# STM32H723 register map
File version: 2.2
CPU: CM7 r0p1, little endian, MPU, FPU, 4 interrupt priority bits
Registers are 32-bit, read-write, reset 0x0 unless marked. A register's access mark holds for its fields unless they carry their own. Offsets are from the block's base; [hi:lo] are bit positions; {n}, {i} and the like mark numbered series; 'fields as' and 'values as' point back to an identical list.

## DBGMCU — DBGMCU address block description
Base 0x5C001000
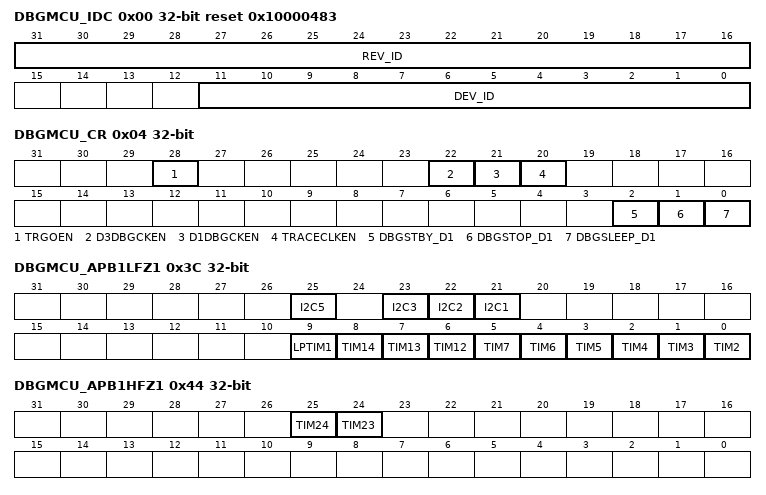
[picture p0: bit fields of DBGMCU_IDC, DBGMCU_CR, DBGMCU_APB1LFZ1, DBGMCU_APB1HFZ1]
0x00 DBGMCU_IDC ro reset 0x10000483
  [31:16] REV_ID — Revision
  [11:0] DEV_ID — Device ID
    0x483=STM32H72x, STM32H73x
0x04 DBGMCU_CR
  [28] TRGOEN — External trigger output enable
    0=Input - TRGIO is connected to TRGIN; 1=Output - TRGIO is connected to TRGOUT
  [22] D3DBGCKEN — D3 debug clock enable
    0=Disabled - D3 domain debug components are disabled and their clocks gated; 1=Enabled - D3 domain debug components are clocked whenever the corresponding domain clock (CK_HCLK_D3) is active
  [21] D1DBGCKEN — D1 debug clock enable
    0=Disabled - D1 domain debug components are disabled and their clocks gated; 1=Enabled - D1 domain debug components are clocked whenever the corresponding domain clock (CK_HCLK_D1) is active
  [20] TRACECLKEN — Trace port clock enable
    0=Disabled - TRACECLK is disabled; 1=Enabled - TRACECLK is active
  [2] DBGSTBY_D1 — D1 domain debug in Standby mode enable
    0=Normal operation - all clocks is disabled and the domain powered down automatically in Standby mode; 1=Automatic clock stop/power-down disabled - all active clocks and oscillators continue to run during Standby mode, and the domain supply is maintained, allowing full debug capability
  [1] DBGSTOP_D1 — D1 domain debug in Stop mode enable
    0=Normal operation - all clocks are disabled automatically in Stop mode; 1=Automatic clock stop disabled - all active clocks and oscillators continue to run during Stop mode, allowing full debug capability
  [0] DBGSLEEP_D1 — D1 domain debug in Sleep mode enable
    0=Normal operation - the processor clock is stopped automatically in Sleep mode; 1=Automatic clock stop disabled - processor clock continues to run, allowing full debug capability
0x34 DBGMCU_APB3FZ1
  [6] WWDG1 — WWDG1 stop in debug
    0=Normal operation - WWDG1 continues to operate while the core is in Debug mode; 1=Stop in debug - WWDG1 is frozen while the core is in Debug mode
0x3C DBGMCU_APB1LFZ1
  [25] I2C5 — I2C5 SMBUS timeout stop in debug
    0=Normal operation - I2C5 SMBUS timeout continues to operate while the core is in Debug mode; 1=Stop in debug - I2C5 SMBUS timeout is frozen while the Cortex-M7 is in Debug mode
  [23] I2C3 — I2C3 SMBUS timeout stop in debug
    0=Normal operation - I2C3 SMBUS timeout continues operating while the core is in Debug mode; 1=Stop in debug - I2C3 SMBUS timeout is frozen while Cortex-M7 is in Debug mode
  [22] I2C2 — I2C2 SMBUS timeout stop in debug
    0=Normal operation - I2C2 SMBUS timeout continues operating while the core is in Debug mode; 1=Stop in debug - I2C2 SMBUS timeout is frozen while Cortex-M7 is in Debug mode
  [21] I2C1 — I2C1 SMBUS timeout stop in debug
    0=Normal operation - I2C1 SMBUS timeout continues operating while the core is in Debug mode; 1=Stop in debug - I2C1 SMBUS timeout is frozen while the core is in Debug mode
  [9] LPTIM1 — LPTIM1 stop in debug
    0=Normal operation - LPTIM1 continues operating while the core is in Debug mode; 1=Stop in debug - LPTIM1 is frozen while Cortex-M7 is in Debug mode
  [8] TIM14 — TIM14 stop in debug
    0=Normal operation - TIM14 continues operating while the core is in Debug mode; 1=Stop in debug - TIM14 is frozen while Cortex-M7 is in Debug mode
  [7] TIM13 — TIM13 stop in debug
    0=Normal operation - TIM13 continues operating while the core is in Debug mode; 1=Stop in debug - TIM13 is frozen while Cortex-M7 is in Debug mode
  [6] TIM12 — TIM12 stop in debug
    0=Normal operation - TIM12 continues operatinge while the core is in Debug mode; 1=Stop in debug - TIM12 is frozen while Cortex-M7 is in Debug mode
  [5] TIM7 — TIM7 stop in debug
    0=Normal operation - TIM7 continues operatinge while the core is in Debug mode; 1=Stop in debug - TIM7 is frozen while Cortex-M7 is in Debug mode
  [n-2] TIM{n} (n=2..6) — TIM{n} stop in debug
    0=Normal operation - TIM{n} continues operating while the core is in Debug mode; 1=Stop in debug - TIM{n} is frozen while Cortex-M7 is in Debug mode
0x44 DBGMCU_APB1HFZ1
  [25] TIM24 — TIM24 stop in debug
    0=Normal operation - TIM24 continues to operate while the core is in debug mode; 1=Stop in debug - TIM24 is frozen while Cortex-M7 is in debug mode
  [24] TIM23 — TIM23 stop in debug
    0=Normal operation - TIM23 continues to operate while the core is in debug mode; 1=Stop in debug - TIM23 is frozen while Cortex-M7 is in debug mode
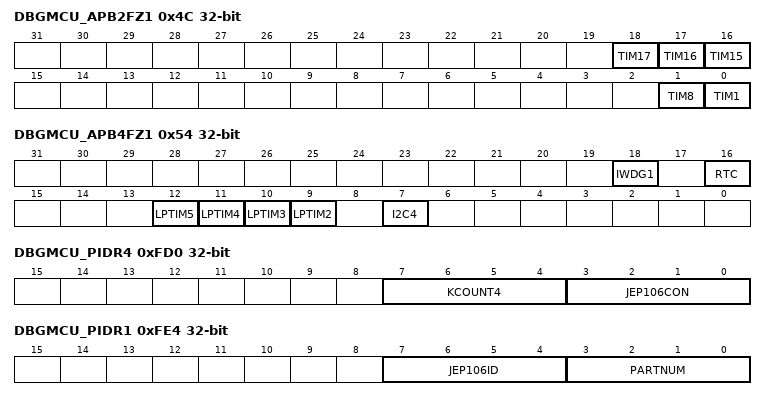
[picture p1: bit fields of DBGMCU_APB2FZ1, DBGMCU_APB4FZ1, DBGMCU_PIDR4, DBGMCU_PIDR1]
0x4C DBGMCU_APB2FZ1
  [18] TIM17 — TIM17 stop in debug
    0=Normal operation - TIM17 continues operating while the core is in Debug mode; 1=Stop in debug - TIM17 is frozen and TIM17 outputs are disabled while Cortex-M7 is in Debug mode
  [17] TIM16 — TIM16 stop in debug
    0=Normal operation - TIM16 continues operating while the core is in Debug mode; 1=Stop in debug - TIM16 is frozen and TIM16 outputs are disabled while Cortex-M7 is in Debug mode
  [16] TIM15 — TIM15 stop in debug
    0=Normal operation - TIM15 continues operating while the core is in Debug mode; 1=Stop in debug - TIM15 is frozen and TIM15 outputs are disabled while Cortex-M7 is in Debug mode
  [1] TIM8 — TIM8 stop in debug
    0=Normal operation - TIM8 continues operating while the core is in Debug mode; 1=Stop in debug - TIM8 is frozen and TIM8 outputs are disabled while Cortex-M7 is in Debug mode
  [0] TIM1 — TIM1 stop in debug
    0=Normal operation - TIM1 continues operating while the core is in Debug mode; 1=Stop in debug - TIM1 is frozen and TIM1 outputs are disabled while Cortex-M7 is in Debug mode
0x54 DBGMCU_APB4FZ1
  [18] IWDG1 — Independent watchdog for D1 stop in debug
    0=Normal operation - watchdog continues counting while the core is in Debug mode; 1=Stop in debug - watchdog is frozen while Cortex-M7 is in Debug mode
  [16] RTC — RTC stop in debug
    0=Normal operation - RTC continues operating while the core is in Debug mode; 1=Stop in debug - RTC is frozen while Cortex-M7 is in Debug mode
  [12] LPTIM5 — LPTIM5 stop in debug
    0=Normal operation - LPTIM5 continues operating while the core is in Debug mode; 1=Stop in debug - LPTIM5 is frozen while Cortex-M7 is in Debug mode
  [11] LPTIM4 — LPTIM4 stop in debug
    0=Normal operation - LPTIM4 continues operating while the core is in Debug mode; 1=Stop in debug - LPTIM4 is frozen while Cortex-M7 is in Debug mode
  [10] LPTIM3 — LPTIM2 stop in debug
    0=Normal operation - LPTIM2 continues operating while the core is in Debug mode; 1=Stop in debug - LPTIM2 is frozen while Cortex-M7 is in Debug mode
  [9] LPTIM2 — LPTIM2 stop in debug
    values as LPTIM3
  [7] I2C4 — I2C4 SMBUS timeout stop in debug
    0=Normal operation - I2C4 SMBUS timeout continues operating while the core is in Debug mode; 1=Stop in debug - I2C4 SMBUS timeout is frozen while the core is in Debug mode
0xFD0 DBGMCU_PIDR4 ro
  [7:4] KCOUNT4 — Register file size
    0=Register file occupies a single 4 Kbyte region
  [3:0] JEP106CON — JEP106 continuation code
    0=STMicroelectronics JEDEC code
0xFE0 DBGMCU_PIDR0 ro
  [7:0] PARTNUM — Part number field, bits [7:0]
    0=DBGMCU
0xFE4 DBGMCU_PIDR1 ro
  [7:4] JEP106ID — JEP106 identity code field, bits [3:0]
    0=STMicroelectronics JEDEC code
  [3:0] PARTNUM — Part number field, bits [11:8]
    0=DBGMCU
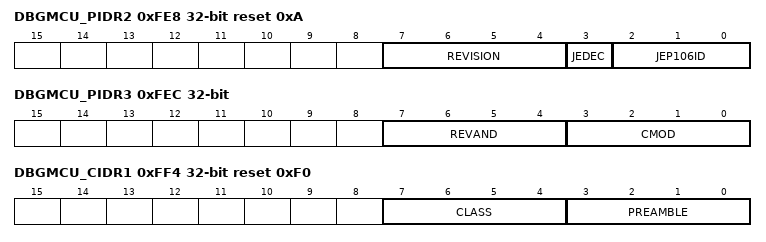
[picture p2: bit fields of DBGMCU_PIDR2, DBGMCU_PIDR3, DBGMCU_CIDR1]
0xFE8 DBGMCU_PIDR2 ro reset 0xA
  [7:4] REVISION — Component revision number
    0=rev 0
  [3] JEDEC — JEDEC assigned value
    1=Designer ID specified by JEDEC
  [2:0] JEP106ID — JEP106 identity code field, bits [6:4]
    2=STMicroelectronics JEDEC code
0xFEC DBGMCU_PIDR3 ro
  [7:4] REVAND — Metal fix version
    0=No metal fix
  [3:0] CMOD — Customer modified
    0=No customer modifications
0xFF0 DBGMCU_CIDR0 ro reset 0xD
  [7:0] PREAMBLE — Component ID field, bits [7:0]
    13=Common ID value
0xFF4 DBGMCU_CIDR1 ro reset 0xF0
  [7:4] CLASS — Component ID field, bits [15:12] - component class
    15=System component with non-standard register layout
  [3:0] PREAMBLE — Component ID field, bits [11:8]
    0=Common ID value
0xFF8 DBGMCU_CIDR2 ro reset 0x5
  [7:0] PREAMBLE — Component ID field, bits [23:16]
    5=Common ID value
0xFFC DBGMCU_CIDR3 ro reset 0xB1
  [7:0] PREAMBLE — Component ID field, bits [31:24]
    177=Common ID value
